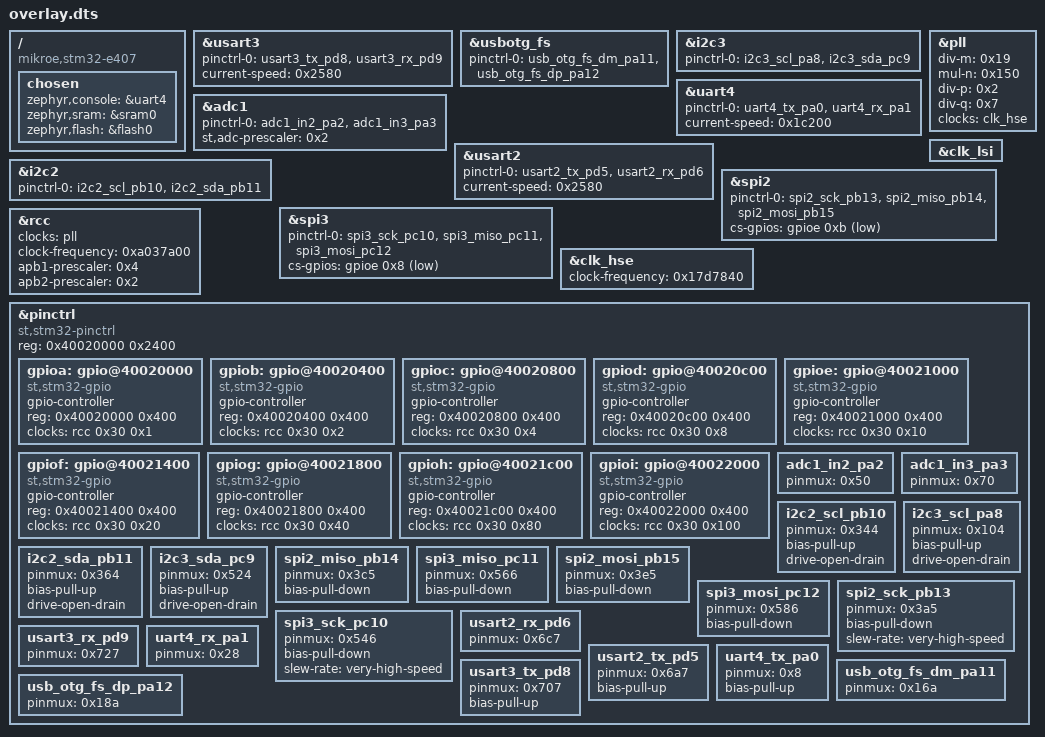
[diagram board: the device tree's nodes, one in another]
/ {
	compatible = "mikroe,stm32-e407", "st,stm32f407";
	chosen {
		zephyr,console = &uart4;
		zephyr,sram = &sram0;
		zephyr,flash = &flash0;
	};
};
&usart3{
	status = "okay";
	pinctrl-0 = < &usart3_tx_pd8 &usart3_rx_pd9 >;
	pinctrl-names = "default";
	current-speed = < 0x2580 >;
};
&usbotg_fs{
	status = "okay";
	pinctrl-0 = < &usb_otg_fs_dm_pa11 &usb_otg_fs_dp_pa12 >;
	pinctrl-names = "default";
};
&i2c3{
	status = "okay";
	pinctrl-0 = < &i2c3_scl_pa8 &i2c3_sda_pc9 >;
	pinctrl-names = "default";
};
&uart4{
	status = "okay";
	pinctrl-0 = < &uart4_tx_pa0 &uart4_rx_pa1 >;
	pinctrl-names = "default";
	current-speed = < 0x1c200 >;
};
&pll{
	status = "okay";
	div-m = < 0x19 >;
	mul-n = < 0x150 >;
	div-p = < 0x2 >;
	div-q = < 0x7 >;
	clocks = < &clk_hse >;
};
&adc1{
	status = "okay";
	pinctrl-0 = < &adc1_in2_pa2 &adc1_in3_pa3 >;
	pinctrl-names = "default";
	st,adc-prescaler = < 0x2 >;
};
&usart2{
	status = "okay";
	pinctrl-0 = < &usart2_tx_pd5 &usart2_rx_pd6 >;
	pinctrl-names = "default";
	current-speed = < 0x2580 >;
};
&clk_lsi{
	status = "okay";
};
&i2c2{
	status = "okay";
	pinctrl-0 = < &i2c2_scl_pb10 &i2c2_sda_pb11 >;
	pinctrl-names = "default";
};
&spi2{
	status = "okay";
	pinctrl-0 = < &spi2_sck_pb13 &spi2_miso_pb14 &spi2_mosi_pb15 >;
	pinctrl-names = "default";
	cs-gpios = < &gpioe 0xb 0x1 >;
};
&spi3{
	status = "okay";
	pinctrl-0 = < &spi3_sck_pc10 &spi3_miso_pc11 &spi3_mosi_pc12 >;
	pinctrl-names = "default";
	cs-gpios = < &gpioe 0x8 0x1 >;
};
&rcc{
	clocks = < &pll >;
	clock-frequency = < 0xa037a00 >;
	apb1-prescaler = < 0x4 >;
	apb2-prescaler = < 0x2 >;
};
&clk_hse{
	status = "okay";
	clock-frequency = < 0x17d7840 >;
};
&pinctrl{
	compatible = "st,stm32-pinctrl";
	#address-cells = < 0x1 >;
	#size-cells = < 0x1 >;
	reg = < 0x40020000 0x2400 >;
	gpioa: gpio@40020000 {
		compatible = "st,stm32-gpio";
		gpio-controller;
		#gpio-cells = < 0x2 >;
		reg = < 0x40020000 0x400 >;
		clocks = < &rcc 0x30 0x1 >;
	};
	gpiob: gpio@40020400 {
		compatible = "st,stm32-gpio";
		gpio-controller;
		#gpio-cells = < 0x2 >;
		reg = < 0x40020400 0x400 >;
		clocks = < &rcc 0x30 0x2 >;
	};
	gpioc: gpio@40020800 {
		compatible = "st,stm32-gpio";
		gpio-controller;
		#gpio-cells = < 0x2 >;
		reg = < 0x40020800 0x400 >;
		clocks = < &rcc 0x30 0x4 >;
	};
	gpiod: gpio@40020c00 {
		compatible = "st,stm32-gpio";
		gpio-controller;
		#gpio-cells = < 0x2 >;
		reg = < 0x40020c00 0x400 >;
		clocks = < &rcc 0x30 0x8 >;
	};
	gpioe: gpio@40021000 {
		compatible = "st,stm32-gpio";
		gpio-controller;
		#gpio-cells = < 0x2 >;
		reg = < 0x40021000 0x400 >;
		clocks = < &rcc 0x30 0x10 >;
	};
	gpiof: gpio@40021400 {
		compatible = "st,stm32-gpio";
		gpio-controller;
		#gpio-cells = < 0x2 >;
		reg = < 0x40021400 0x400 >;
		clocks = < &rcc 0x30 0x20 >;
	};
	gpiog: gpio@40021800 {
		compatible = "st,stm32-gpio";
		gpio-controller;
		#gpio-cells = < 0x2 >;
		reg = < 0x40021800 0x400 >;
		clocks = < &rcc 0x30 0x40 >;
	};
	gpioh: gpio@40021c00 {
		compatible = "st,stm32-gpio";
		gpio-controller;
		#gpio-cells = < 0x2 >;
		reg = < 0x40021c00 0x400 >;
		clocks = < &rcc 0x30 0x80 >;
	};
	gpioi: gpio@40022000 {
		compatible = "st,stm32-gpio";
		gpio-controller;
		#gpio-cells = < 0x2 >;
		reg = < 0x40022000 0x400 >;
		clocks = < &rcc 0x30 0x100 >;
	};
	adc1_in2_pa2: adc1_in2_pa2 {
		pinmux = < 0x50 >;
	};
	adc1_in3_pa3: adc1_in3_pa3 {
		pinmux = < 0x70 >;
	};
	i2c2_scl_pb10: i2c2_scl_pb10 {
		pinmux = < 0x344 >;
		bias-pull-up;
		drive-open-drain;
	};
	i2c3_scl_pa8: i2c3_scl_pa8 {
		pinmux = < 0x104 >;
		bias-pull-up;
		drive-open-drain;
	};
	i2c2_sda_pb11: i2c2_sda_pb11 {
		pinmux = < 0x364 >;
		bias-pull-up;
		drive-open-drain;
	};
	i2c3_sda_pc9: i2c3_sda_pc9 {
		pinmux = < 0x524 >;
		bias-pull-up;
		drive-open-drain;
	};
	spi2_miso_pb14: spi2_miso_pb14 {
		pinmux = < 0x3c5 >;
		bias-pull-down;
	};
	spi3_miso_pc11: spi3_miso_pc11 {
		pinmux = < 0x566 >;
		bias-pull-down;
	};
	spi2_mosi_pb15: spi2_mosi_pb15 {
		pinmux = < 0x3e5 >;
		bias-pull-down;
	};
	spi3_mosi_pc12: spi3_mosi_pc12 {
		pinmux = < 0x586 >;
		bias-pull-down;
	};
	spi2_sck_pb13: spi2_sck_pb13 {
		pinmux = < 0x3a5 >;
		bias-pull-down;
		slew-rate = "very-high-speed";
	};
	spi3_sck_pc10: spi3_sck_pc10 {
		pinmux = < 0x546 >;
		bias-pull-down;
		slew-rate = "very-high-speed";
	};
	usart2_rx_pd6: usart2_rx_pd6 {
		pinmux = < 0x6c7 >;
	};
	usart3_rx_pd9: usart3_rx_pd9 {
		pinmux = < 0x727 >;
	};
	uart4_rx_pa1: uart4_rx_pa1 {
		pinmux = < 0x28 >;
	};
	usart2_tx_pd5: usart2_tx_pd5 {
		pinmux = < 0x6a7 >;
		bias-pull-up;
	};
	usart3_tx_pd8: usart3_tx_pd8 {
		pinmux = < 0x707 >;
		bias-pull-up;
	};
	uart4_tx_pa0: uart4_tx_pa0 {
		pinmux = < 0x8 >;
		bias-pull-up;
	};
	usb_otg_fs_dm_pa11: usb_otg_fs_dm_pa11 {
		pinmux = < 0x16a >;
	};
	usb_otg_fs_dp_pa12: usb_otg_fs_dp_pa12 {
		pinmux = < 0x18a >;
	};
};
